VERSION ""

NS_ :

BS_:

BU_: SCC MDPS

BO_ 560 BCW_Data: 1 SCC
 SG_ sig_BCW_LR : 0|2@1+ (1,0) [0|2] "" Vector__XXX
 SG_ sig_BCWState : 2|2@1+ (1,0) [0|3] "" Vector__XXX

BO_ 561 FCA_Data: 1 SCC
 SG_ sig_FCAState : 0|2@1+ (1,0) [0|3] "" Vector__XXX

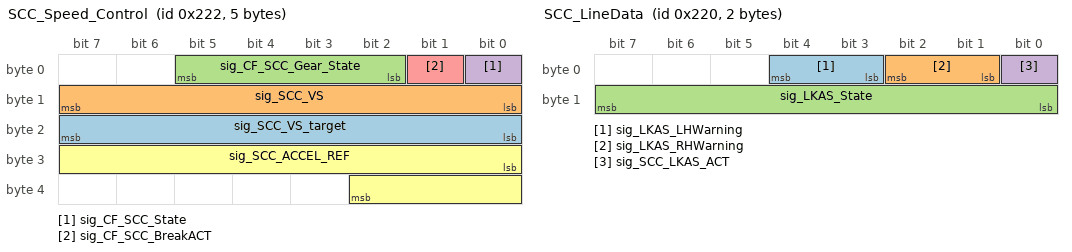
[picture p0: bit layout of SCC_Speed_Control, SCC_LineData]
BO_ 546 SCC_Speed_Control: 5 SCC
 SG_ sig_SCC_VS_target : 16|8@1+ (1,0) [0|254] "km/h" Vector__XXX
 SG_ sig_SCC_VS : 8|8@1+ (1,0) [0|254] "km/h" Vector__XXX
 SG_ sig_CF_SCC_Gear_State : 2|4@1+ (1,0) [0|15] "" Vector__XXX
 SG_ sig_CF_SCC_State : 0|1@1+ (1,0) [0|1] "" Vector__XXX
 SG_ sig_CF_SCC_BreakACT : 1|1@1+ (1,0) [0|1] "" Vector__XXX
 SG_ sig_SCC_ACCEL_REF : 24|11@1+ (0.01,-10.23) [-10.23|10.24] "m/s^2" Vector__XXX

BO_ 545 SCC_E_stop: 1 SCC
 SG_ sig_CF_Estop : 0|1@1+ (1,0) [0|1] "" Vector__XXX

BO_ 544 SCC_LineData: 2 SCC
 SG_ sig_LKAS_LHWarning : 3|2@1+ (1,0) [0|3] "" Vector__XXX
 SG_ sig_LKAS_RHWarning : 1|2@1+ (1,0) [0|3] "" Vector__XXX
 SG_ sig_LKAS_State : 8|8@1+ (1,0) [0|7] "" Vector__XXX
 SG_ sig_SCC_LKAS_ACT : 0|1@1+ (1,0) [0|1] "" Vector__XXX

BO_ 529 MDPS_Col_Tq: 2 MDPS
 SG_ sig_ColTq : 0|11@1+ (1,-1024) [-1024|1024] "" Vector__XXX

BO_ 528 MDPS_Out_Tq: 2 MDPS
 SG_ sig_OutTq : 0|12@1+ (0.1,-204.8) [-204.8|204.7] "" Vector__XXX

BO_ 513 MDPS_Steering_Tq: 2 MDPS
 SG_ sig_SteeringTq : 0|12@1+ (0.01,-20.48) [-20.48|20.47] "Nm" Vector__XXX

BO_ 512 MDPS_Steering_Angle: 2 MDPS
 SG_ sig_SteeringAngle : 0|16@1- (0.1,0) [-3276.8|3276.7] "Deg" Vector__XXX

BA_DEF_  "BusType" STRING ;
BA_DEF_DEF_  "BusType" "CAN";
